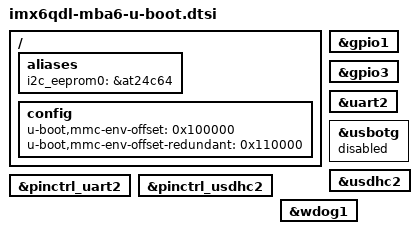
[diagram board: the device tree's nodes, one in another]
// SPDX-License-Identifier: (GPL-2.0-or-later OR MIT)
/*
 * Copyright (c) 2023 TQ-Systems GmbH <u-boot@ew.tq-group.com>,
 * D-82229 Seefeld, Germany.
 * Author: Markus Niebel
 */

/* SOM specific U-Boot DT adjustments */

#include "imx6qdl-tqma6-u-boot.dtsi"

/ {
	aliases {
		i2c_eeprom0 = &at24c64;
	};

	config {
		u-boot,mmc-env-offset = <0x100000>;
		u-boot,mmc-env-offset-redundant = <0x110000>;
	};
};

&gpio1 {
	u-boot,dm-spl;
};

&gpio3 {
	u-boot,dm-spl;
};

&pinctrl_uart2 {
	u-boot,dm-spl;
};

&pinctrl_usdhc2 {
	u-boot,dm-spl;
};

&uart2 {
	u-boot,dm-spl;
};

&usbotg {
	status = "disabled";
};

&usdhc2 {
	u-boot,dm-spl;
};

&wdog1 {
	u-boot,dm-spl;
};
